AUTOSAR XML (schema 4-0-3)
standard types defined: Boolean
package /AUTOSAR_Platform/DataConstrs
  range DC_Boolean: raw 0..1
package /PATAC/MSM/ComponentTypes
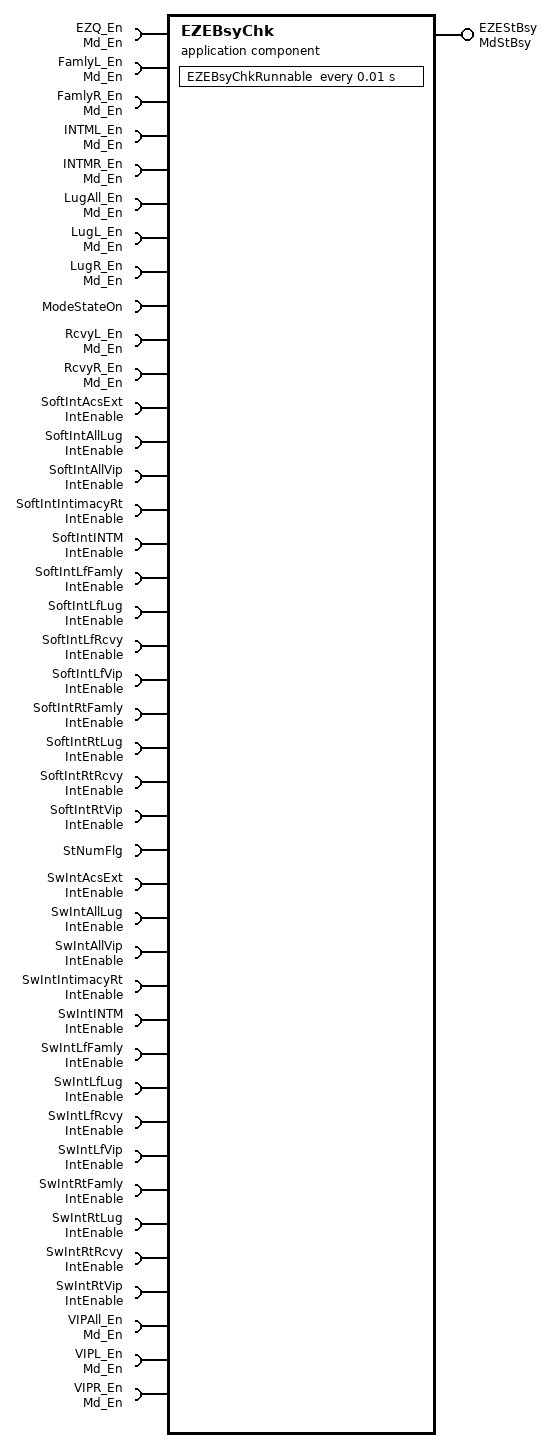
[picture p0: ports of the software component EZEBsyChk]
  application sw component type EZEBsyChk
    provide port EZEStBsy: nonqueued-sender-com-spec{data-element=MdStBsy/Val, init-value=0}, provided-interface=MdStBsy
    41 x require port:
      EZQ_En: nonqueued-receiver-com-spec{data-element=Md_En/Val, filter=data-filter-type=ALWAYS, init-value=0}, required-interface=Md_En
      FamlyL_En: nonqueued-receiver-com-spec{data-element=Md_En/Val, filter=data-filter-type=ALWAYS, init-value=0}, required-interface=Md_En
      FamlyR_En: nonqueued-receiver-com-spec{data-element=Md_En/Val, filter=data-filter-type=ALWAYS, init-value=0}, required-interface=Md_En
      INTML_En: nonqueued-receiver-com-spec{data-element=Md_En/Val, filter=data-filter-type=ALWAYS, init-value=0}, required-interface=Md_En
      INTMR_En: nonqueued-receiver-com-spec{data-element=Md_En/Val, filter=data-filter-type=ALWAYS, init-value=0}, required-interface=Md_En
      LugAll_En: nonqueued-receiver-com-spec{data-element=Md_En/Val, filter=data-filter-type=ALWAYS, init-value=0}, required-interface=Md_En
      LugL_En: nonqueued-receiver-com-spec{data-element=Md_En/Val, filter=data-filter-type=ALWAYS, init-value=0}, required-interface=Md_En
      LugR_En: nonqueued-receiver-com-spec{data-element=Md_En/Val, filter=data-filter-type=ALWAYS, init-value=0}, required-interface=Md_En
      ModeStateOn: nonqueued-receiver-com-spec{data-element=ModeStateOn/Val, filter=data-filter-type=ALWAYS, init-value=0}, required-interface=ModeStateOn
      RcvyL_En: nonqueued-receiver-com-spec{data-element=Md_En/Val, filter=data-filter-type=ALWAYS, init-value=0}, required-interface=Md_En
      RcvyR_En: nonqueued-receiver-com-spec{data-element=Md_En/Val, filter=data-filter-type=ALWAYS, init-value=0}, required-interface=Md_En
      SoftIntAcsExt: nonqueued-receiver-com-spec{data-element=IntEnable/Val, filter=data-filter-type=ALWAYS, init-value=0}, required-interface=IntEnable
      SoftIntAllLug: nonqueued-receiver-com-spec{data-element=IntEnable/Val, filter=data-filter-type=ALWAYS, init-value=0}, required-interface=IntEnable
      SoftIntAllVip: nonqueued-receiver-com-spec{data-element=IntEnable/Val, filter=data-filter-type=ALWAYS, init-value=0}, required-interface=IntEnable
      SoftIntIntimacyRt: nonqueued-receiver-com-spec{data-element=IntEnable/Val, filter=data-filter-type=ALWAYS, init-value=0}, required-interface=IntEnable
      SoftIntINTM: nonqueued-receiver-com-spec{data-element=IntEnable/Val, filter=data-filter-type=ALWAYS, init-value=0}, required-interface=IntEnable
      SoftIntLfFamly: nonqueued-receiver-com-spec{data-element=IntEnable/Val, filter=data-filter-type=ALWAYS, init-value=0}, required-interface=IntEnable
      SoftIntLfLug: nonqueued-receiver-com-spec{data-element=IntEnable/Val, filter=data-filter-type=ALWAYS, init-value=0}, required-interface=IntEnable
      SoftIntLfRcvy: nonqueued-receiver-com-spec{data-element=IntEnable/Val, filter=data-filter-type=ALWAYS, init-value=0}, required-interface=IntEnable
      SoftIntLfVip: nonqueued-receiver-com-spec{data-element=IntEnable/Val, filter=data-filter-type=ALWAYS, init-value=0}, required-interface=IntEnable
      SoftIntRtFamly: nonqueued-receiver-com-spec{data-element=IntEnable/Val, filter=data-filter-type=ALWAYS, init-value=0}, required-interface=IntEnable
      SoftIntRtLug: nonqueued-receiver-com-spec{data-element=IntEnable/Val, filter=data-filter-type=ALWAYS, init-value=0}, required-interface=IntEnable
      SoftIntRtRcvy: nonqueued-receiver-com-spec{data-element=IntEnable/Val, filter=data-filter-type=ALWAYS, init-value=0}, required-interface=IntEnable
      SoftIntRtVip: nonqueued-receiver-com-spec{data-element=IntEnable/Val, filter=data-filter-type=ALWAYS, init-value=0}, required-interface=IntEnable
      StNumFlg: required-interface=StNumFlg
        required-com-specs:
          data-element=Is4s, filter=data-filter-type=ALWAYS, init-value=0
          data-element=Is6s, filter=data-filter-type=ALWAYS, init-value=0
          data-element=Is6s7s, filter=data-filter-type=ALWAYS, init-value=0
          data-element=Is7s, filter=data-filter-type=ALWAYS, init-value=0
      SwIntAcsExt: nonqueued-receiver-com-spec{data-element=IntEnable/Val, filter=data-filter-type=ALWAYS, init-value=0}, required-interface=IntEnable
      SwIntAllLug: nonqueued-receiver-com-spec{data-element=IntEnable/Val, filter=data-filter-type=ALWAYS, init-value=0}, required-interface=IntEnable
      SwIntAllVip: nonqueued-receiver-com-spec{data-element=IntEnable/Val, filter=data-filter-type=ALWAYS, init-value=0}, required-interface=IntEnable
      SwIntIntimacyRt: nonqueued-receiver-com-spec{data-element=IntEnable/Val, filter=data-filter-type=ALWAYS, init-value=0}, required-interface=IntEnable
      SwIntINTM: nonqueued-receiver-com-spec{data-element=IntEnable/Val, filter=data-filter-type=ALWAYS, init-value=0}, required-interface=IntEnable
      SwIntLfFamly: nonqueued-receiver-com-spec{data-element=IntEnable/Val, filter=data-filter-type=ALWAYS, init-value=0}, required-interface=IntEnable
      SwIntLfLug: nonqueued-receiver-com-spec{data-element=IntEnable/Val, filter=data-filter-type=ALWAYS, init-value=0}, required-interface=IntEnable
      SwIntLfRcvy: nonqueued-receiver-com-spec{data-element=IntEnable/Val, filter=data-filter-type=ALWAYS, init-value=0}, required-interface=IntEnable
      SwIntLfVip: nonqueued-receiver-com-spec{data-element=IntEnable/Val, filter=data-filter-type=ALWAYS, init-value=0}, required-interface=IntEnable
      SwIntRtFamly: nonqueued-receiver-com-spec{data-element=IntEnable/Val, filter=data-filter-type=ALWAYS, init-value=0}, required-interface=IntEnable
      SwIntRtLug: nonqueued-receiver-com-spec{data-element=IntEnable/Val, filter=data-filter-type=ALWAYS, init-value=0}, required-interface=IntEnable
      SwIntRtRcvy: nonqueued-receiver-com-spec{data-element=IntEnable/Val, filter=data-filter-type=ALWAYS, init-value=0}, required-interface=IntEnable
      SwIntRtVip: nonqueued-receiver-com-spec{data-element=IntEnable/Val, filter=data-filter-type=ALWAYS, init-value=0}, required-interface=IntEnable
      VIPAll_En: nonqueued-receiver-com-spec{data-element=Md_En/Val, filter=data-filter-type=ALWAYS, init-value=0}, required-interface=Md_En
      VIPL_En: nonqueued-receiver-com-spec{data-element=Md_En/Val, filter=data-filter-type=ALWAYS, init-value=0}, required-interface=Md_En
      VIPR_En: nonqueued-receiver-com-spec{data-element=Md_En/Val, filter=data-filter-type=ALWAYS, init-value=0}, required-interface=Md_En
    behavior EZEBsyChk_InternalBehavior
      timing event TMT_EZEBsyChkRunnable: start-on-event=EZEBsyChkRunnable, period=0.01
      runnable EZEBsyChkRunnable
        data-receive-point-by-arguments:
          44 x access:
            REC_EZQ_En_Val: accessed-variable=EZQ_En.Val
            REC_FamlyL_En_Val: accessed-variable=FamlyL_En.Val
            REC_FamlyR_En_Val: accessed-variable=FamlyR_En.Val
            REC_INTML_En_Val: accessed-variable=INTML_En.Val
            REC_INTMR_En_Val: accessed-variable=INTMR_En.Val
            REC_LugAll_En_Val: accessed-variable=LugAll_En.Val
            REC_LugL_En_Val: accessed-variable=LugL_En.Val
            REC_LugR_En_Val: accessed-variable=LugR_En.Val
            REC_ModeStateOn_Val: accessed-variable=ModeStateOn.Val
            REC_RcvyL_En_Val: accessed-variable=RcvyL_En.Val
            REC_RcvyR_En_Val: accessed-variable=RcvyR_En.Val
            REC_SoftIntAcsExt_Val: accessed-variable=SoftIntAcsExt.Val
            REC_SoftIntAllLug_Val: accessed-variable=SoftIntAllLug.Val
            REC_SoftIntAllVip_Val: accessed-variable=SoftIntAllVip.Val
            REC_SoftIntIntimacyRt_Val: accessed-variable=SoftIntIntimacyRt.Val
            REC_SoftIntINTM_Val: accessed-variable=SoftIntINTM.Val
            REC_SoftIntLfFamly_Val: accessed-variable=SoftIntLfFamly.Val
            REC_SoftIntLfLug_Val: accessed-variable=SoftIntLfLug.Val
            REC_SoftIntLfRcvy_Val: accessed-variable=SoftIntLfRcvy.Val
            REC_SoftIntLfVip_Val: accessed-variable=SoftIntLfVip.Val
            REC_SoftIntRtFamly_Val: accessed-variable=SoftIntRtFamly.Val
            REC_SoftIntRtLug_Val: accessed-variable=SoftIntRtLug.Val
            REC_SoftIntRtRcvy_Val: accessed-variable=SoftIntRtRcvy.Val
            REC_SoftIntRtVip_Val: accessed-variable=SoftIntRtVip.Val
            REC_StNumFlg_Is4s: accessed-variable=StNumFlg.Is4s
            REC_StNumFlg_Is6s: accessed-variable=StNumFlg.Is6s
            REC_StNumFlg_Is6s7s: accessed-variable=StNumFlg.Is6s7s
            REC_StNumFlg_Is7s: accessed-variable=StNumFlg.Is7s
            REC_SwIntAcsExt_Val: accessed-variable=SwIntAcsExt.Val
            REC_SwIntAllLug_Val: accessed-variable=SwIntAllLug.Val
            REC_SwIntAllVip_Val: accessed-variable=SwIntAllVip.Val
            REC_SwIntIntimacyRt_Val: accessed-variable=SwIntIntimacyRt.Val
            REC_SwIntINTM_Val: accessed-variable=SwIntINTM.Val
            REC_SwIntLfFamly_Val: accessed-variable=SwIntLfFamly.Val
            REC_SwIntLfLug_Val: accessed-variable=SwIntLfLug.Val
            REC_SwIntLfRcvy_Val: accessed-variable=SwIntLfRcvy.Val
            REC_SwIntLfVip_Val: accessed-variable=SwIntLfVip.Val
            REC_SwIntRtFamly_Val: accessed-variable=SwIntRtFamly.Val
            REC_SwIntRtLug_Val: accessed-variable=SwIntRtLug.Val
            REC_SwIntRtRcvy_Val: accessed-variable=SwIntRtRcvy.Val
            REC_SwIntRtVip_Val: accessed-variable=SwIntRtVip.Val
            REC_VIPAll_En_Val: accessed-variable=VIPAll_En.Val
            REC_VIPL_En_Val: accessed-variable=VIPL_En.Val
            REC_VIPR_En_Val: accessed-variable=VIPR_En.Val
        data-send-points:
          access SEND_EZEStBsy_Val: accessed-variable=EZEStBsy.Val
  swc implementation EZEBsyChk_Implementation: behavior=EZEBsyChk_InternalBehavior
    code-descriptors:
      code Default: artifact-descriptors=autosar-engineering-object={short-label=Default, category=SWSRC}
package /PATAC/MSM/DataTypes/ImplementationDataTypes
  impl type IntEnable: category=VALUE, base-type=Boolean, sw-calibration-access=READ-ONLY, type-emitter=RTE
package /PATAC/MSM/ModeAdjust/PortInterface
  5 x sender receiver interface:
    IntEnable: invalidation-policy{data-element=IntEnable/Val, handle-invalid=DONT-INVALIDATE}
      data Val: type=IntEnable
    Md_En: invalidation-policy{data-element=Md_En/Val, handle-invalid=DONT-INVALIDATE}
      data Val: type=Boolean
    MdStBsy: invalidation-policy{data-element=MdStBsy/Val, handle-invalid=DONT-INVALIDATE}
      data Val: type=Boolean
    ModeStateOn: invalidation-policy{data-element=ModeStateOn/Val, handle-invalid=DONT-INVALIDATE}
      data Val: type=Boolean
    StNumFlg
      4 x data, all with type=Boolean:
        Is4s
        Is6s
        Is6s7s
        Is7s
      invalidation-policys:
        data-element=Is7s, handle-invalid=DONT-INVALIDATE
        data-element=Is6s, handle-invalid=DONT-INVALIDATE
        data-element=Is4s, handle-invalid=DONT-INVALIDATE
        data-element=Is6s7s, handle-invalid=DONT-INVALIDATE
